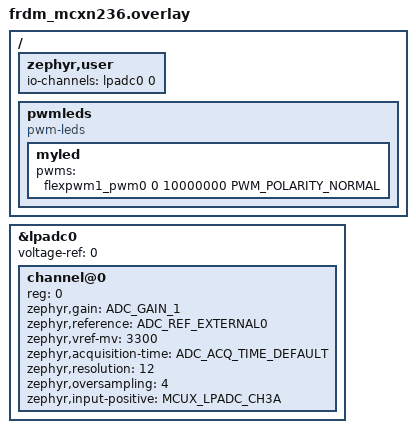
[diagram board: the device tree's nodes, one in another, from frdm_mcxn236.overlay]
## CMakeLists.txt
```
# SPDX-License-Identifier: Apache-2.0

cmake_minimum_required(VERSION 3.20.0)

find_package(Zephyr REQUIRED HINTS $ENV{ZEPHYR_BASE})

project(exercise-17)

FILE(GLOB app_sources src/*.c)

target_sources(app PRIVATE ${app_sources})
```

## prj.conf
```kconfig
CONFIG_ADC=y
CONFIG_PWM=y
CONFIG_LED=y
```

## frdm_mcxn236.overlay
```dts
#include <zephyr/dt-bindings/adc/adc.h>
#include <zephyr/dt-bindings/pwm/pwm.h>
#include <zephyr/dt-bindings/adc/mcux-lpadc.h>

/ {
	zephyr,user {
		io-channels = <&lpadc0 0>;
	};

    pwmleds {
        compatible = "pwm-leds";
        myled: myled {
            pwms = <&flexpwm1_pwm0 0 10000000 PWM_POLARITY_NORMAL>;
            status = "okay";
        };
    };
};

&lpadc0 {
	#address-cells = <1>;
	#size-cells = <0>;
	voltage-ref= <0>;

	channel@0 {
		reg = <0>;
		zephyr,gain = "ADC_GAIN_1";
		zephyr,reference = "ADC_REF_EXTERNAL0";
		zephyr,vref-mv = <3300>;
		zephyr,acquisition-time = <ADC_ACQ_TIME_DEFAULT>;
		zephyr,resolution = <12>;
		zephyr,oversampling = <4>;
		zephyr,input-positive = <MCUX_LPADC_CH3A>; /* J4 pin 2 */
	};
};
```

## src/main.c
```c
#include <zephyr/kernel.h>
#include <zephyr/drivers/led.h>
#include <zephyr/drivers/adc.h>

static float map(float value, float from_min, float from_max, float to_min, float to_max)
{
	if (value > from_max)
	{
		value = from_max;
	}
	else if (value < from_min)
	{
		value = from_min;
	}
	else
	{
		;
	}

	return ((value - from_min) * ((to_max - to_min) / (from_max - from_min)) + to_min);
}

int main(void)
{
	const struct led_dt_spec led_dev = LED_DT_SPEC_GET(DT_NODELABEL(myled));
	const struct adc_dt_spec pot_dev = ADC_DT_SPEC_GET(DT_PATH(zephyr_user));

	if (!led_is_ready_dt(&led_dev))
	{
		printk("LED device is not ready");
		exit(EXIT_FAILURE);
	}

	if (!adc_is_ready_dt(&pot_dev) || (0 > adc_channel_setup_dt(&pot_dev)))
	{
		printk("POT device is not ready");
		exit(EXIT_FAILURE);
	}

	uint16_t value;
	struct adc_sequence sequence = {
		.buffer = &value,
		.buffer_size = sizeof(value),
		.calibrate = true,
	};

	int32_t millivolts;

	while (1)
	{
		if ((0 != adc_sequence_init_dt(&pot_dev, &sequence)) || (0 != adc_read_dt(&pot_dev, &sequence)))
		{
			printk("ADC failed to read\n");
			exit(EXIT_FAILURE);
		}

		millivolts = value;
		if (0 > adc_raw_to_millivolts_dt(&pot_dev, &millivolts))
		{
			printk("ADC failed to convert the raw value to millivolts\n");
			exit(EXIT_FAILURE);
		}

		value = (int)map(millivolts, 0, pot_dev.vref_mv, 0, 100);

		if (0 != led_set_brightness_dt(&led_dev, value))
		{
			printk("Failed to set brightness of the LED\n");
			exit(EXIT_FAILURE);
		}

		k_sleep(K_NSEC(DT_PWMS_PERIOD(DT_NODELABEL(myled))));
	}

	return EXIT_SUCCESS;
}
```
